# MM32SPIN0230 register map
Series: ARM Cortex M0; File version: 1.0
CPU: CM0 r0p0, little endian, no MPU, no FPU, 2 interrupt priority bits
Registers are 32-bit, read-write, reset 0x0 unless marked. A register's access mark holds for its fields unless they carry their own. Offsets are from the block's base; [hi:lo] are bit positions; lines under a group give offsets from that group; {n}, {i} and the like mark numbered series; 'fields as' and 'values as' point back to an identical list.

## COMP
Base 0x40013C00
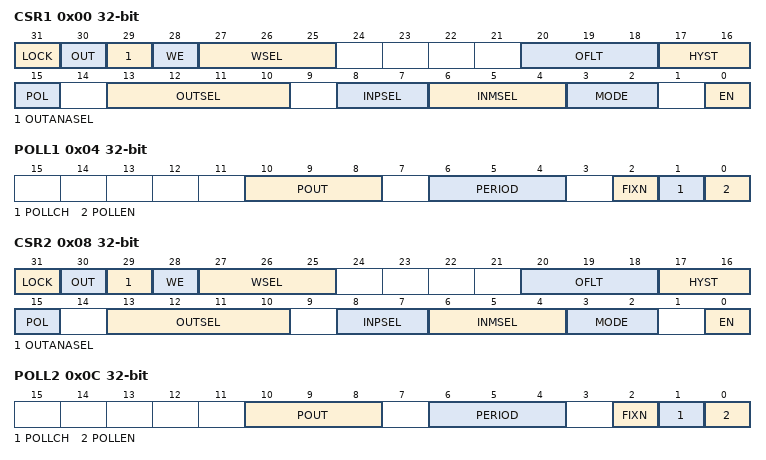
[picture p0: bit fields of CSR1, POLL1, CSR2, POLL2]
0x00 CSR1 — COMP x (x=1, 2) control and status register
  [31] LOCK ro, [30] OUT, [29] OUTANASEL, [28] WE, [27:25] WSEL, [20:18] OFLT, [17:16] HYST, [15] POL, [13:10] OUTSEL, [8:7] INPSEL, [6:4] INMSEL, [3:2] MODE, [0] EN
0x04 POLL1 — COMP x (x=1, 2) polling register
  [10:8] POUT ro, [6:4] PERIOD, [2] FIXN, [1] POLLCH, [0] POLLEN
0x08 CSR2 — COMP x (x=1, 2) control and status register
  fields as CSR1
0x0C POLL2 — COMP x (x=1, 2) polling register
  [10:8] POUT ro, [6:4] PERIOD, [2] FIXN, [1] POLLCH, [0] POLLEN
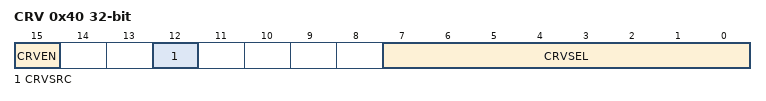
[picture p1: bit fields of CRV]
0x40 CRV — COMP external reference voltage register
  [15] CRVEN, [12] CRVSRC, [7:0] CRVSEL

## DBGMCU
Base 0x40013400
0x00 IDCODE ro reset 0x4C513000 — DBG ID encode register
  [31:0] DEVID
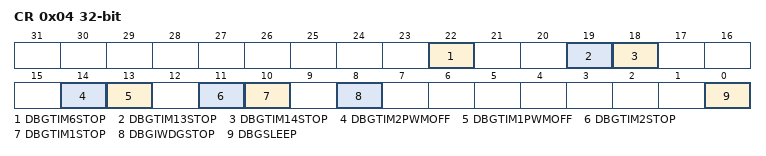
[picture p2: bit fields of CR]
0x04 CR — DBG control register
  [22] DBGTIM6STOP, [19] DBGTIM13STOP, [18] DBGTIM14STOP, [14] DBGTIM2PWMOFF, [13] DBGTIM1PWMOFF, [11] DBGTIM2STOP, [10] DBGTIM1STOP, [8] DBGIWDGSTOP, [0] DBGSLEEP

## DMA
Base 0x40020000
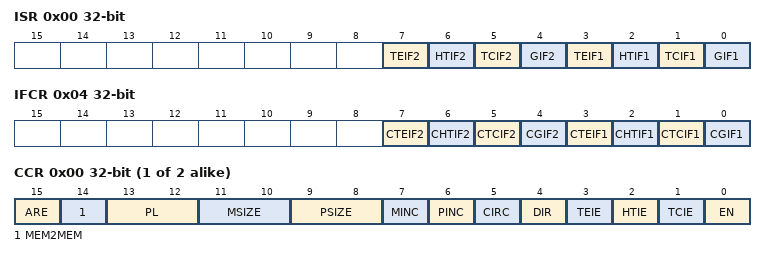
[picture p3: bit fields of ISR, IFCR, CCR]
0x00 ISR ro — DMA interrupt status register
  [7] TEIF2, [6] HTIF2, [5] TCIF2, [4] GIF2, [3] TEIF1, [2] HTIF1, [1] TCIF1, [0] GIF1
0x04 IFCR — DMA interrupt flag clear register
  [7] CTEIF2 write-1-clears, [6] CHTIF2 write-1-clears, [5] CTCIF2 write-1-clears, [4] CGIF2 write-1-clears, [3] CTEIF1 write-1-clears, [2] CHTIF1 write-1-clears, [1] CTCIF1 write-1-clears, [0] CGIF1 write-1-clears
0x08 DMACH{i} (i=1..2; step 0x14) group
  0x00 CCR — DMA channel x configuration register
    [15] ARE, [14] MEM2MEM, [13:12] PL, [11:10] MSIZE, [9:8] PSIZE, [7] MINC, [6] PINC, [5] CIRC, [4] DIR, [3] TEIE, [2] HTIE, [1] TCIE, [0] EN
  0x04 CNDTR — DMA channel x number of data register
    [15:0] NDT
  0x08 CPAR — DMA channel x peripheral address register
    [31:0] PA
  0x0C CMAR — DMA channel x memory address register
    [31:0] MA

## EXTI
Base 0x40010400
0x00 IMR — Interrupt mask register
  [31:0] IMRX
0x04 EMR — Event mask register
  [31:0] EMRX
0x08 RTSR — Rising edge trigger selection register
  [31:0] TRX
0x0C FTSR — Falling edge trigger selection register
  [31:0] TRX
0x10 SWIER — Software interrupt event register
  [31:0] SWIERX
0x14 PR — Pending register
  [31:0] PRX write-1-clears

## FLASH
Base 0x40022000
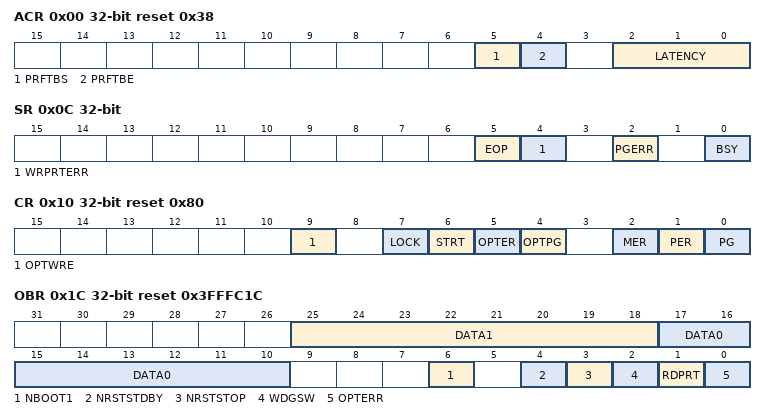
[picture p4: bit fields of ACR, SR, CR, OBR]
0x00 ACR reset 0x38 — Flash access control register
  [5] PRFTBS ro, [4] PRFTBE, [2:0] LATENCY
0x04 KEYR wo — FPEC key register
  [31:0] FKEYR
0x08 OPTKEYR wo — Flash OPTKEY register
0x0C SR — Flash status register
  [5] EOP, [4] WRPRTERR, [2] PGERR, [0] BSY ro
0x10 CR reset 0x80 — Flash control register
  [9] OPTWRE, [7] LOCK, [6] STRT, [5] OPTER, [4] OPTPG, [2] MER, [1] PER, [0] PG
0x14 AR wo — Flash address register
  [31:0] FAR
0x1C OBR ro reset 0x3FFFC1C — Option byte register
  [25:18] DATA1, [17:10] DATA0, [6] NBOOT1, [4] NRSTSTDBY, [3] NRSTSTOP, [2] WDGSW, [1] RDPRT, [0] OPTERR
0x20 WRPR ro reset 0xFFFFFFFF — Write protection register
  [7:0] WRP

## GPIOA
Base 0x48000000
Same registers: GPIOB 0x48000400
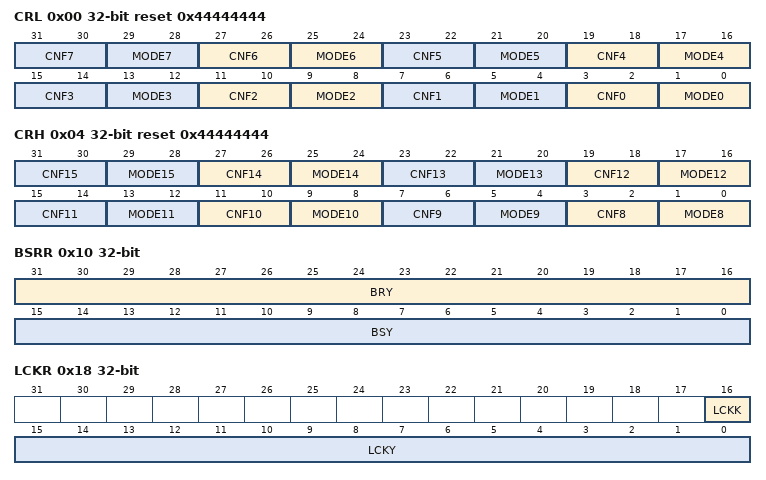
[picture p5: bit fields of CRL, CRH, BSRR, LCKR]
0x00 CRL reset 0x44444444 — Port configuration register low
  [4n+3:4n+2] CNF{n} (n=0..7), [4n+1:4n] MODE{n} (n=0..7)
0x04 CRH reset 0x44444444 — Port configuration register high
  [4n-29:4n-30] CNF{n} (n=8..15), [4n-31:4n-32] MODE{n} (n=8..15)
0x08 IDR ro — Port input data register
  [15:0] IDRY
0x0C ODR — Port output data register
  [15:0] ODRY
0x10 BSRR wo — Port bit set/reset register
  [31:16] BRY, [15:0] BSY
0x14 BRR wo — Port bit reset register
  [15:0] BRY
0x18 LCKR — Port configuration lock register
  [16] LCKK, [15:0] LCKY wo
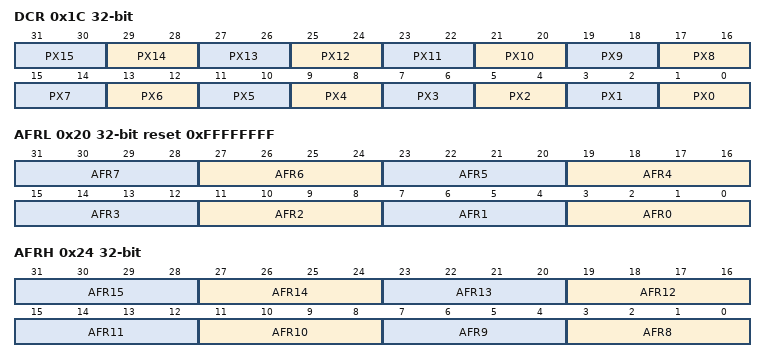
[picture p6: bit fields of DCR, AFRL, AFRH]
0x1C DCR — Port output open drain control register
  [2n+1:2n] PX{n} (n=0..15)
0x20 AFRL reset 0xFFFFFFFF — Port alternate function register low
  [4n+3:4n] AFR{n} (n=0..7)
0x24 AFRH — Port alternate function register high
  [4n-29:4n-32] AFR{n} (n=8..15)
